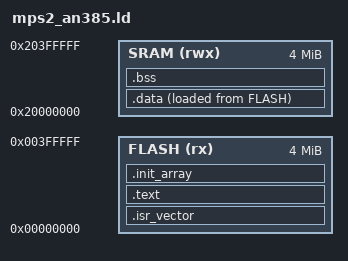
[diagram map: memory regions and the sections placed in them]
ENTRY(Reset_Handler)

MEMORY
{
  FLASH (rx)  : ORIGIN = 0x00000000, LENGTH = 4096K
  SRAM  (rwx) : ORIGIN = 0x20000000, LENGTH = 4096K
}

_estack = ORIGIN(SRAM) + LENGTH(SRAM);

SECTIONS
{
  .isr_vector :
  {
    . = ALIGN(4);
    KEEP(*(.isr_vector))
    . = ALIGN(4);
  } > FLASH

  .text :
  {
    . = ALIGN(4);
    *(.text)
    *(.text*)
    *(.rodata)
    *(.rodata*)
    . = ALIGN(4);
  } > FLASH

  .init_array :
  {
    . = ALIGN(4);
    __init_array_start = .;
    KEEP(*(SORT(.init_array.*)))
    KEEP(*(.init_array*))
    __init_array_end = .;
    . = ALIGN(4);
  } > FLASH

  _sidata = LOADADDR(.data);

  .data :
  {
    . = ALIGN(4);
    _sdata = .;
    *(.data)
    *(.data*)
    . = ALIGN(4);
    _edata = .;
  } > SRAM AT > FLASH

  .bss (NOLOAD) :
  {
    . = ALIGN(4);
    _sbss = .;
    *(.bss)
    *(.bss*)
    *(COMMON)
    . = ALIGN(4);
    _ebss = .;
  } > SRAM
}
